# R7FA4E10D register map
Vendor: Renesas Electronics Corporation; Series: RA4E1; File version: 1.20.00
CPU: CM33 r0p4, little endian, MPU, FPU, VTOR, 4 interrupt priority bits, 96 interrupts
Registers are 8-bit, read-write, reset 0x0 unless marked. A register's access mark holds for its fields unless they carry their own. Offsets are from the block's base; [hi:lo] are bit positions; {n}, {i} and the like mark numbered series.

## CPSCU — CPU System Security Control Unit
Base 0x40008000
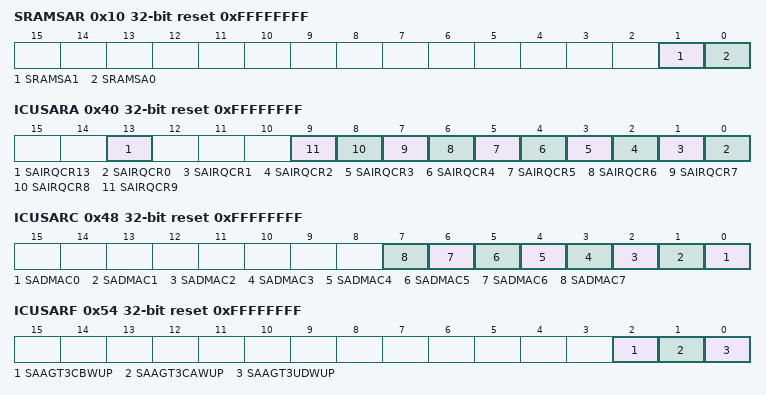
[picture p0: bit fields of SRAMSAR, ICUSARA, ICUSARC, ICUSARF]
0x10 SRAMSAR 32-bit reset 0xFFFFFFFF — SRAM Security Attribution Register
  [1] SRAMSA1 — Security attributes of registers for SRAM Protection 2
  [0] SRAMSA0 — Security attributes of registers for SRAM Protection
0x14 STBRAMSAR 32-bit reset 0xFFFFFFF0 — Standby RAM memory Security Attribution Register
  [3:0] NSBSTBR — Security attributes of each region for Standby RAM
0x30 DTCSAR 32-bit reset 0xFFFFFFFF — DTC Controller Security Attribution Register
  [0] DTCSTSA — DTC Security Attribution
0x34 DMACSAR 32-bit reset 0xFFFFFFFF — DMAC Controller Security Attribution Register
  [0] DMASTSA — DMAST Security Attribution
0x40 ICUSARA 32-bit reset 0xFFFFFFFF — Interrupt Controller Unit Security Attribution Register A
  [13] SAIRQCR13 — Security attributes of registers for the IRQCR13 register
  [n] SAIRQCR{n} (n=0..9) — Security attributes of registers for the IRQCRn register (n = 0 to 9)
0x44 ICUSARB 32-bit reset 0xFFFFFFFF — Interrupt Controller Unit Security Attribution Register B
  [0] SANMI — Security attributes of registers for nonmaskable interrupt
0x48 ICUSARC 32-bit reset 0xFFFFFFFF — Interrupt Controller Unit Security Attribution Register C
  [n] SADMAC{n} (n=0..7) — Security attributes of registers for DMAC channel
0x4C ICUSARD 32-bit reset 0xFFFFFFFF — Interrupt Controller Unit Security Attribution Register D
  [0] SASELSR0 — Security attributes of registers for SELSR0
0x54 ICUSARF 32-bit reset 0xFFFFFFFF — Interrupt Controller Unit Security Attribution Register F
  [2] SAAGT3CBWUP — Security attributes of registers for WUPEN1.b2
  [1] SAAGT3CAWUP — Security attributes of registers for WUPEN1.b1
  [0] SAAGT3UDWUP — Security attributes of registers for WUPEN1.b0
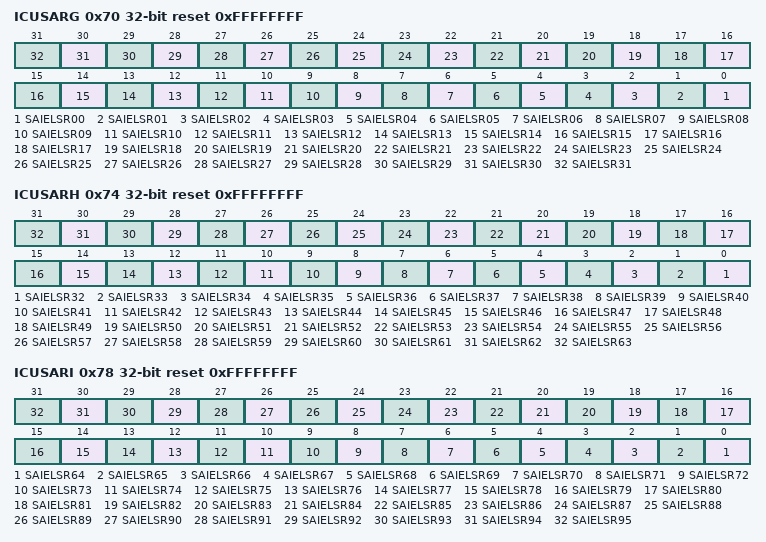
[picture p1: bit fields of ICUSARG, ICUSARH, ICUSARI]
0x70 ICUSARG 32-bit reset 0xFFFFFFFF — Interrupt Controller Unit Security Attribution Register G
  [n] SAIELSR{n:02} (n=0..31) — Security attributes of registers for IELSR31 to IELSR0
0x74 ICUSARH 32-bit reset 0xFFFFFFFF — Interrupt Controller Unit Security Attribution Register H
  [n-32] SAIELSR{n} (n=32..63) — Security attributes of registers for IELSR63 to IELSR32
0x78 ICUSARI 32-bit reset 0xFFFFFFFF — Interrupt Controller Unit Security Attribution Register I
  [n-64] SAIELSR{n} (n=64..95) — Security attributes of registers for IELSR95 to IELSR64
0x100 BUSSARA 32-bit reset 0xFFFFFFFF — BUS Security Attribution Register A
  [0] BUSSA0 — BUS Security Attribution A0
0x104 BUSSARB 32-bit reset 0xFFFFFFFF — BUS Security Attribution Register B
  [0] BUSSB0 — BUS Security Attribution B0
0x130 MMPUSARA 32-bit reset 0xFFFFFFFF — Master Memory Protection Unit Security Attribution Register A
  [7:0] MMPUASAn — MMPUA Security Attribution (n = 0 to 7)
0x134 MMPUSARB 32-bit reset 0xFFFFFFFF — Master Memory Protection Unit Security Attribution Register B
  [0] MMPUBSA0 — MMPUB Security Attribution
0x180 TZFSAR 32-bit reset 0xFFFFFFFE — TrustZone Filter Security Attribution Register
  [0] TZFSA0 — Security attributes of registers for TrustZone Filter
0x1B0 CPUDSAR 32-bit reset 0xFFFFFFFE — CPU Debug Security Attribution Register
  [0] CPUDSA0 — CPU Debug Security Attribution 0

## DBG — Debug Function
Base 0x4001B000
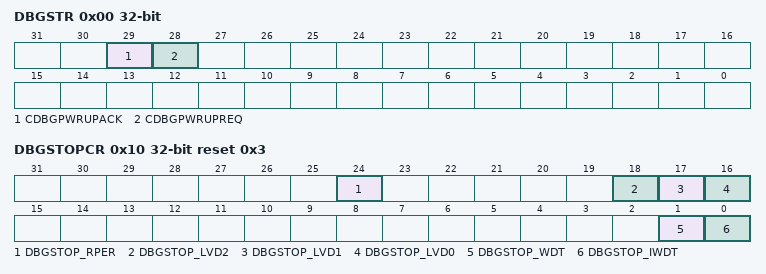
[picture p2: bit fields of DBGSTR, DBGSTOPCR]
0x00 DBGSTR 32-bit ro — Debug Status Register
  [29] CDBGPWRUPACK — Debug power,up acknowledge
  [28] CDBGPWRUPREQ — Debug power,up request
0x10 DBGSTOPCR 32-bit reset 0x3 — Debug Stop Control Register
  [24] DBGSTOP_RPER — Mask bit for SRAM parity error reset/interrupt
  [18] DBGSTOP_LVD2 — Mask bit for LVD2 reset/interrupt
  [17] DBGSTOP_LVD1 — Mask bit for LVD1 reset/interrupt
  [16] DBGSTOP_LVD0 — Mask bit for LVD0 reset
  [1] DBGSTOP_WDT — Mask bit for WDT reset/interrupt in the OCD run mode
  [0] DBGSTOP_IWDT — Mask bit for IWDT reset/interrupt in the OCD run mode
